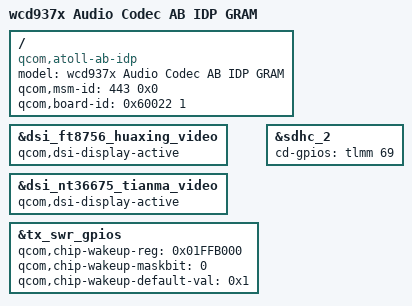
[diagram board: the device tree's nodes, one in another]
/* Copyright (c) 2019, The Linux Foundation. All rights reserved.
 * Copyright (C) 2021 XiaoMi, Inc.
 *
 * This program is free software; you can redistribute it and/or modify
 * it under the terms of the GNU General Public License version 2 and
 * only version 2 as published by the Free Software Foundation.
 *
 * This program is distributed in the hope that it will be useful,
 * but WITHOUT ANY WARRANTY; without even the implied warranty of
 * MERCHANTABILITY or FITNESS FOR A PARTICULAR PURPOSE.  See the
 * GNU General Public License for more details.
 */

/dts-v1/;
/plugin/;

#include <dt-bindings/interrupt-controller/arm-gic.h>
#include "atoll-idp.dtsi"
#include "atoll-wcd937x-idp-audio-overlay.dtsi"
#include "gram-atoll-camera-sensor-idp.dtsi"
#include "j6b-charge-overlay.dtsi"

/ {
	model = "wcd937x Audio Codec AB IDP GRAM";
	compatible = "qcom,atoll-ab-idp", "qcom,atoll-ab", "qcom,idp";
	qcom,msm-id = <443 0x0>;
	qcom,board-id = <0x60022 1>;
};

&dsi_ft8756_huaxing_video {
	qcom,dsi-display-active;
};
&dsi_nt36675_tianma_video {
	qcom,dsi-display-active;
};
&tx_swr_gpios {
	qcom,chip-wakeup-reg = <0x01FFB000>;
	qcom,chip-wakeup-maskbit = <0>;
	qcom,chip-wakeup-default-val = <0x1>;
};

&sdhc_2 {
	cd-gpios = <&tlmm 69 0>;
};
